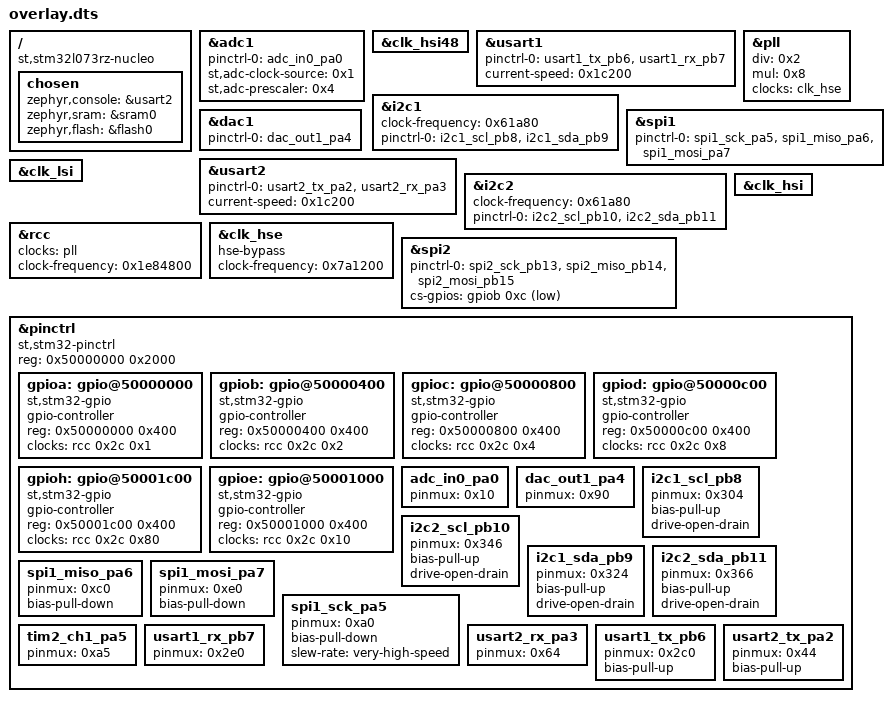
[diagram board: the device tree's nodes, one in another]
/ {
	compatible = "st,stm32l073rz-nucleo";
	chosen {
		zephyr,console = &usart2;
		zephyr,sram = &sram0;
		zephyr,flash = &flash0;
	};
};
&adc1{
	status = "okay";
	pinctrl-0 = < &adc_in0_pa0 >;
	pinctrl-names = "default";
	st,adc-clock-source = < 0x1 >;
	st,adc-prescaler = < 0x4 >;
};
&clk_hsi48{
	status = "okay";
};
&usart1{
	pinctrl-0 = < &usart1_tx_pb6 &usart1_rx_pb7 >;
	pinctrl-names = "default";
	current-speed = < 0x1c200 >;
};
&pll{
	status = "okay";
	div = < 0x2 >;
	mul = < 0x8 >;
	clocks = < &clk_hse >;
};
&i2c1{
	clock-frequency = < 0x61a80 >;
	status = "okay";
	pinctrl-0 = < &i2c1_scl_pb8 &i2c1_sda_pb9 >;
	pinctrl-names = "default";
};
&dac1{
	status = "okay";
	pinctrl-0 = < &dac_out1_pa4 >;
	pinctrl-names = "default";
};
&spi1{
	status = "okay";
	pinctrl-0 = < &spi1_sck_pa5 &spi1_miso_pa6 &spi1_mosi_pa7 >;
	pinctrl-names = "default";
};
&usart2{
	status = "okay";
	pinctrl-0 = < &usart2_tx_pa2 &usart2_rx_pa3 >;
	pinctrl-names = "default";
	current-speed = < 0x1c200 >;
};
&i2c2{
	clock-frequency = < 0x61a80 >;
	status = "okay";
	pinctrl-0 = < &i2c2_scl_pb10 &i2c2_sda_pb11 >;
	pinctrl-names = "default";
};
&clk_lsi{
	status = "okay";
};
&rcc{
	clocks = < &pll >;
	clock-frequency = < 0x1e84800 >;
};
&clk_hse{
	status = "okay";
	hse-bypass;
	clock-frequency = < 0x7a1200 >;
};
&spi2{
	status = "okay";
	pinctrl-0 = < &spi2_sck_pb13 &spi2_miso_pb14 &spi2_mosi_pb15 >;
	pinctrl-names = "default";
	cs-gpios = < &gpiob 0xc 0x1 >;
};
&clk_hsi{
	status = "okay";
};
&pinctrl{
	compatible = "st,stm32-pinctrl";
	#address-cells = < 0x1 >;
	#size-cells = < 0x1 >;
	reg = < 0x50000000 0x2000 >;
	gpioa: gpio@50000000 {
		compatible = "st,stm32-gpio";
		gpio-controller;
		#gpio-cells = < 0x2 >;
		reg = < 0x50000000 0x400 >;
		clocks = < &rcc 0x2c 0x1 >;
	};
	gpiob: gpio@50000400 {
		compatible = "st,stm32-gpio";
		gpio-controller;
		#gpio-cells = < 0x2 >;
		reg = < 0x50000400 0x400 >;
		clocks = < &rcc 0x2c 0x2 >;
	};
	gpioc: gpio@50000800 {
		compatible = "st,stm32-gpio";
		gpio-controller;
		#gpio-cells = < 0x2 >;
		reg = < 0x50000800 0x400 >;
		clocks = < &rcc 0x2c 0x4 >;
	};
	gpiod: gpio@50000c00 {
		compatible = "st,stm32-gpio";
		gpio-controller;
		#gpio-cells = < 0x2 >;
		reg = < 0x50000c00 0x400 >;
		clocks = < &rcc 0x2c 0x8 >;
	};
	gpioh: gpio@50001c00 {
		compatible = "st,stm32-gpio";
		gpio-controller;
		#gpio-cells = < 0x2 >;
		reg = < 0x50001c00 0x400 >;
		clocks = < &rcc 0x2c 0x80 >;
	};
	gpioe: gpio@50001000 {
		compatible = "st,stm32-gpio";
		gpio-controller;
		#gpio-cells = < 0x2 >;
		reg = < 0x50001000 0x400 >;
		clocks = < &rcc 0x2c 0x10 >;
	};
	adc_in0_pa0: adc_in0_pa0 {
		pinmux = < 0x10 >;
	};
	dac_out1_pa4: dac_out1_pa4 {
		pinmux = < 0x90 >;
	};
	i2c1_scl_pb8: i2c1_scl_pb8 {
		pinmux = < 0x304 >;
		bias-pull-up;
		drive-open-drain;
	};
	i2c2_scl_pb10: i2c2_scl_pb10 {
		pinmux = < 0x346 >;
		bias-pull-up;
		drive-open-drain;
	};
	i2c1_sda_pb9: i2c1_sda_pb9 {
		pinmux = < 0x324 >;
		bias-pull-up;
		drive-open-drain;
	};
	i2c2_sda_pb11: i2c2_sda_pb11 {
		pinmux = < 0x366 >;
		bias-pull-up;
		drive-open-drain;
	};
	spi1_miso_pa6: spi1_miso_pa6 {
		pinmux = < 0xc0 >;
		bias-pull-down;
	};
	spi1_mosi_pa7: spi1_mosi_pa7 {
		pinmux = < 0xe0 >;
		bias-pull-down;
	};
	spi1_sck_pa5: spi1_sck_pa5 {
		pinmux = < 0xa0 >;
		bias-pull-down;
		slew-rate = "very-high-speed";
	};
	tim2_ch1_pa5: tim2_ch1_pa5 {
		pinmux = < 0xa5 >;
	};
	usart1_rx_pb7: usart1_rx_pb7 {
		pinmux = < 0x2e0 >;
	};
	usart2_rx_pa3: usart2_rx_pa3 {
		pinmux = < 0x64 >;
	};
	usart1_tx_pb6: usart1_tx_pb6 {
		pinmux = < 0x2c0 >;
		bias-pull-up;
	};
	usart2_tx_pa2: usart2_tx_pa2 {
		pinmux = < 0x44 >;
		bias-pull-up;
	};
};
